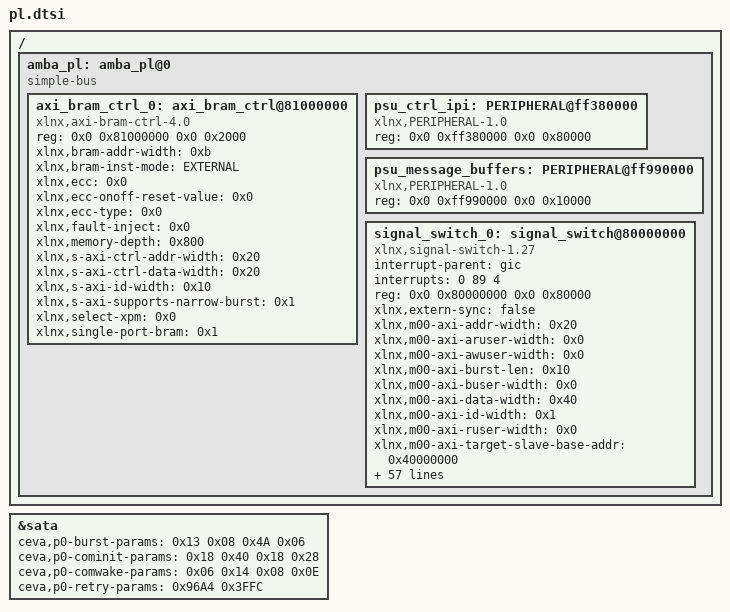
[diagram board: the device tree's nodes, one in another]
/*
 * CAUTION: This file is automatically generated by Xilinx.
 * Version:  
 * Today is: Mon Jul  3 14:17:05 2017
*/


/ {
	amba_pl: amba_pl@0 {
		#address-cells = <2>;
		#size-cells = <2>;
		compatible = "simple-bus";
		ranges ;
		axi_bram_ctrl_0: axi_bram_ctrl@81000000 {
			compatible = "xlnx,axi-bram-ctrl-4.0";
			reg = <0x0 0x81000000 0x0 0x2000>;
			xlnx,bram-addr-width = <0xb>;
			xlnx,bram-inst-mode = "EXTERNAL";
			xlnx,ecc = <0x0>;
			xlnx,ecc-onoff-reset-value = <0x0>;
			xlnx,ecc-type = <0x0>;
			xlnx,fault-inject = <0x0>;
			xlnx,memory-depth = <0x800>;
			xlnx,s-axi-ctrl-addr-width = <0x20>;
			xlnx,s-axi-ctrl-data-width = <0x20>;
			xlnx,s-axi-id-width = <0x10>;
			xlnx,s-axi-supports-narrow-burst = <0x1>;
			xlnx,select-xpm = <0x0>;
			xlnx,single-port-bram = <0x1>;
		};
		psu_ctrl_ipi: PERIPHERAL@ff380000 {
			compatible = "xlnx,PERIPHERAL-1.0";
			reg = <0x0 0xff380000 0x0 0x80000>;
		};
		psu_message_buffers: PERIPHERAL@ff990000 {
			compatible = "xlnx,PERIPHERAL-1.0";
			reg = <0x0 0xff990000 0x0 0x10000>;
		};
		signal_switch_0: signal_switch@80000000 {
			compatible = "xlnx,signal-switch-1.27";
			interrupt-parent = <&gic>;
			interrupts = <0 89 4>;
			reg = <0x0 0x80000000 0x0 0x80000>;
			xlnx,extern-sync = "false";
			xlnx,m00-axi-addr-width = <0x20>;
			xlnx,m00-axi-aruser-width = <0x0>;
			xlnx,m00-axi-awuser-width = <0x0>;
			xlnx,m00-axi-burst-len = <0x10>;
			xlnx,m00-axi-buser-width = <0x0>;
			xlnx,m00-axi-data-width = <0x40>;
			xlnx,m00-axi-id-width = <0x1>;
			xlnx,m00-axi-ruser-width = <0x0>;
			xlnx,m00-axi-target-slave-base-addr = <0x40000000>;
			xlnx,m00-axi-wuser-width = <0x0>;
			xlnx,m01-axi-addr-width = <0x20>;
			xlnx,m01-axi-aruser-width = <0x0>;
			xlnx,m01-axi-awuser-width = <0x0>;
			xlnx,m01-axi-burst-len = <0x10>;
			xlnx,m01-axi-buser-width = <0x0>;
			xlnx,m01-axi-data-width = <0x40>;
			xlnx,m01-axi-id-width = <0x1>;
			xlnx,m01-axi-ruser-width = <0x0>;
			xlnx,m01-axi-target-slave-base-addr = <0x40000000>;
			xlnx,m01-axi-wuser-width = <0x0>;
			xlnx,m02-axi-addr-width = <0x20>;
			xlnx,m02-axi-aruser-width = <0x0>;
			xlnx,m02-axi-awuser-width = <0x0>;
			xlnx,m02-axi-burst-len = <0x10>;
			xlnx,m02-axi-buser-width = <0x0>;
			xlnx,m02-axi-data-width = <0x40>;
			xlnx,m02-axi-id-width = <0x1>;
			xlnx,m02-axi-ruser-width = <0x0>;
			xlnx,m02-axi-target-slave-base-addr = <0x40000000>;
			xlnx,m02-axi-wuser-width = <0x0>;
			xlnx,m03-axi-addr-width = <0x20>;
			xlnx,m03-axi-aruser-width = <0x0>;
			xlnx,m03-axi-awuser-width = <0x0>;
			xlnx,m03-axi-burst-len = <0x10>;
			xlnx,m03-axi-buser-width = <0x0>;
			xlnx,m03-axi-data-width = <0x40>;
			xlnx,m03-axi-id-width = <0x1>;
			xlnx,m03-axi-ruser-width = <0x0>;
			xlnx,m03-axi-target-slave-base-addr = <0x40000000>;
			xlnx,m03-axi-wuser-width = <0x0>;
			xlnx,m04-axi-addr-width = <0x20>;
			xlnx,m04-axi-aruser-width = <0x0>;
			xlnx,m04-axi-awuser-width = <0x0>;
			xlnx,m04-axi-burst-len = <0x10>;
			xlnx,m04-axi-buser-width = <0x0>;
			xlnx,m04-axi-data-width = <0x40>;
			xlnx,m04-axi-id-width = <0x1>;
			xlnx,m04-axi-ruser-width = <0x0>;
			xlnx,m04-axi-target-slave-base-addr = <0x40000000>;
			xlnx,m04-axi-wuser-width = <0x0>;
			xlnx,s00-axi-addr-width = <0x12>;
			xlnx,s00-axi-aruser-width = <0x10>;
			xlnx,s00-axi-awuser-width = <0x10>;
			xlnx,s00-axi-buser-width = <0x0>;
			xlnx,s00-axi-data-width = <0x20>;
			xlnx,s00-axi-id-width = <0x10>;
			xlnx,s00-axi-ruser-width = <0x0>;
			xlnx,s00-axi-wuser-width = <0x0>;
			xlnx,slot-num = <0x1e>;
			xlnx,slv-addr-width = <0x10>;
			xlnx,slv-data-width = <0x20>;
			xlnx,sync-width = <0x8>;
		};
	};
};
&sata {
	ceva,p0-burst-params = "/bits/ 8 <0x13 0x08 0x4A 0x06>";
	ceva,p0-cominit-params = "/bits/ 8 <0x18 0x40 0x18 0x28>";
	ceva,p0-comwake-params = "/bits/ 8 <0x06 0x14 0x08 0x0E>";
	ceva,p0-retry-params = "/bits/ 16 <0x96A4 0x3FFC>";
};
